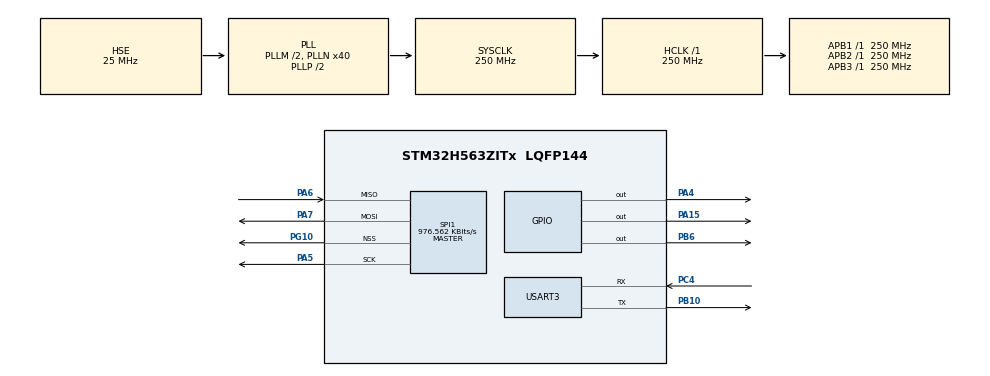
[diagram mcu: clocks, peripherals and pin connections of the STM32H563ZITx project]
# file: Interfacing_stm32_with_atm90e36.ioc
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CORTEX_M33_NS.userName=CORTEX_M33
Mcu.Family=STM32H5
Mcu.Name=STM32H563ZITx
Mcu.Package=LQFP144
NVIC.PriorityGroup=NVIC_PRIORITYGROUP_4
PA15(JTDI).Signal=GPIO_Output
PA4.Signal=GPIO_Output
PA5.Mode=Full_Duplex_Master
PA5.Signal=SPI1_SCK
PA6.Mode=Full_Duplex_Master
PA6.Signal=SPI1_MISO
PA7.Mode=Full_Duplex_Master
PA7.Signal=SPI1_MOSI
PB10.Mode=Asynchronous
PB10.Signal=USART3_TX
PB6.Signal=GPIO_Output
PC4.Mode=Asynchronous
PC4.Signal=USART3_RX
PG10.Mode=NSS_Signal_Hard_Output
PG10.Signal=SPI1_NSS
PH0-OSC_IN(PH0).Mode=HSE-External-Oscillator
PH0-OSC_IN(PH0).Signal=RCC_OSC_IN
PH1-OSC_OUT(PH1).Mode=HSE-External-Oscillator
PH1-OSC_OUT(PH1).Signal=RCC_OSC_OUT
ProjectManager.HeapSize=0x200
ProjectManager.StackSize=0x400
ProjectManager.TargetToolchain=STM32CubeIDE
RCC.ADCFreq_Value=250000000
RCC.AHBFreq_Value=250000000
RCC.APB1Freq_Value=250000000
RCC.APB1TimFreq_Value=250000000
RCC.APB2Freq_Value=250000000
RCC.APB2TimFreq_Value=250000000
RCC.APB3Freq_Value=250000000
RCC.CSI_VALUE=4000000
RCC.CortexFreq_Value=250000000
RCC.EPOD_VALUE=25000000
RCC.HCLKFreq_Value=250000000
RCC.HSE_VALUE=25000000
RCC.HSI48_VALUE=48000000
RCC.HSIDiv=RCC_HSI_DIV1
RCC.HSI_VALUE=64000000
RCC.LSE_VALUE=32768
RCC.LSIRC_VALUE=32000
RCC.PLL2FRACN=0
RCC.PLL3FRACN=0
RCC.PLLFRACN=0
RCC.PLLM=2
RCC.PLLN=40
RCC.PLLSourceVirtual=RCC_PLL1_SOURCE_HSE
RCC.SYSCLKFreq_VALUE=250000000
RCC.SYSCLKSource=RCC_SYSCLKSOURCE_PLLCLK
RCC.USBFreq_Value=48000000
RCC.VCOOutputFreq_Value=500000000
SPI1.BaudRatePrescaler=SPI_BAUDRATEPRESCALER_256
SPI1.CalculateBaudRate=976.562 KBits/s
SPI1.DataSize=SPI_DATASIZE_8BIT
SPI1.Direction=SPI_DIRECTION_2LINES
SPI1.Mode=SPI_MODE_MASTER
SPI1.VirtualNSS=VM_NSSHARD
SPI1.VirtualType=VM_MASTER
USART3.VirtualMode=VM_ASYNC
VP_PWR_VS_SECSignals.Mode=Security/Privilege
board=NUCLEO-H563ZI

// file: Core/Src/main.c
/* USER CODE BEGIN Header */
/**
  ******************************************************************************
  * @file           : main.c
  * @brief          : Main program body
  ******************************************************************************
  * @attention
  *
  * Copyright (c) 2024 STMicroelectronics.
  * All rights reserved.
  *
  * This software is licensed under terms that can be found in the LICENSE file
  * in the root directory of this software component.
  * If no LICENSE file comes with this software, it is provided AS-IS.
  *
  ******************************************************************************
  */
/* USER CODE END Header */
#include "main.h"

/* USER CODE BEGIN Includes */
#include"stdio.h"
#include"stm32h5xx_hal_uart.h"
#include "stm32h5xx_hal_spi.h"
#include"atm90e36.h"

/* USER CODE END Includes */

SPI_HandleTypeDef hspi1;

UART_HandleTypeDef huart3;

/* USER CODE BEGIN PV */
//uint16_t send_data = 0x1234;
//uint16_t rec_data = 0;

/* USER CODE END PV */

void SystemClock_Config(void);
static void MX_GPIO_Init(void);
static void MX_USART3_UART_Init(void);
static void MX_SPI1_Init(void);

/* USER CODE BEGIN 0 */
int __io_putchar(int ch) {
    HAL_UART_Transmit(&huart3, (uint8_t *)&ch, 1, HAL_MAX_DELAY);
    return ch;
}

/* USER CODE END 0 */

int main(void)
{

  /* MCU Configuration--------------------------------------------------------*/

  /* Reset of all peripherals, Initializes the Flash interface and the Systick. */
  HAL_Init();

  /* Configure the system clock */
  SystemClock_Config();

  /* Initialize all configured peripherals */
  MX_GPIO_Init();
  MX_USART3_UART_Init();
  MX_SPI1_Init();
  /* USER CODE BEGIN 2 */

  ATM90E36A_Init();
//  uint16_t temp = 0;

  /* USER CODE END 2 */

  /* Infinite loop */
  while (1)
  {

    /* USER CODE BEGIN 3 */
	  printf("hello\r\n");

	  readEnrgyMeterValues();

//	  printf("Interfacing stm32 with energy meter\r\n");
//	  HAL_SPI_TransmitReceive(&hspi1,(uint8_t*)&send_data, (uint8_t*)&rec_data, 1, HAL_MAX_DELAY);
//	  printf("rece %d\r\n",rec_data);
	  HAL_Delay(1000);
//	  fflush(stdout);
//	  temp = CommEnergyIC(&hspi1, ATM90E36A_READ, Temp, 0);//UrmsA
//	temp =  CommEnergyIC(&hspi1, ATM90E36A_READ, UrmsA, 0);

//	  printf("TEMPERATURE: %d\r\n",temp);

  }
  /* USER CODE END 3 */
}

void SystemClock_Config(void)
{
  RCC_OscInitTypeDef RCC_OscInitStruct = {0};
  RCC_ClkInitTypeDef RCC_ClkInitStruct = {0};

  /** Configure the main internal regulator output voltage
  */
  __HAL_PWR_VOLTAGESCALING_CONFIG(PWR_REGULATOR_VOLTAGE_SCALE0);

  while(!__HAL_PWR_GET_FLAG(PWR_FLAG_VOSRDY)) {}

  /** Initializes the RCC Oscillators according to the specified parameters
  * in the RCC_OscInitTypeDef structure.
  */
  RCC_OscInitStruct.OscillatorType = RCC_OSCILLATORTYPE_HSE;
  RCC_OscInitStruct.HSEState = RCC_HSE_ON;
  RCC_OscInitStruct.PLL.PLLState = RCC_PLL_ON;
  RCC_OscInitStruct.PLL.PLLSource = RCC_PLL1_SOURCE_HSE;
  RCC_OscInitStruct.PLL.PLLM = 2;
  RCC_OscInitStruct.PLL.PLLN = 40;
  RCC_OscInitStruct.PLL.PLLP = 2;
  RCC_OscInitStruct.PLL.PLLQ = 2;
  RCC_OscInitStruct.PLL.PLLR = 2;
  RCC_OscInitStruct.PLL.PLLRGE = RCC_PLL1_VCIRANGE_3;
  RCC_OscInitStruct.PLL.PLLVCOSEL = RCC_PLL1_VCORANGE_WIDE;
  RCC_OscInitStruct.PLL.PLLFRACN = 0;
  if (HAL_RCC_OscConfig(&RCC_OscInitStruct) != HAL_OK)
  {
    Error_Handler();
  }

  /** Initializes the CPU, AHB and APB buses clocks
  */
  RCC_ClkInitStruct.ClockType = RCC_CLOCKTYPE_HCLK|RCC_CLOCKTYPE_SYSCLK
                              |RCC_CLOCKTYPE_PCLK1|RCC_CLOCKTYPE_PCLK2
                              |RCC_CLOCKTYPE_PCLK3;
  RCC_ClkInitStruct.SYSCLKSource = RCC_SYSCLKSOURCE_PLLCLK;
  RCC_ClkInitStruct.AHBCLKDivider = RCC_SYSCLK_DIV1;
  RCC_ClkInitStruct.APB1CLKDivider = RCC_HCLK_DIV1;
  RCC_ClkInitStruct.APB2CLKDivider = RCC_HCLK_DIV1;
  RCC_ClkInitStruct.APB3CLKDivider = RCC_HCLK_DIV1;

  if (HAL_RCC_ClockConfig(&RCC_ClkInitStruct, FLASH_LATENCY_5) != HAL_OK)
  {
    Error_Handler();
  }
}

static void MX_SPI1_Init(void)
{

  /* SPI1 parameter configuration*/
  hspi1.Instance = SPI1;
  hspi1.Init.Mode = SPI_MODE_MASTER;
  hspi1.Init.Direction = SPI_DIRECTION_2LINES;
  hspi1.Init.DataSize = SPI_DATASIZE_8BIT;
  hspi1.Init.CLKPolarity = SPI_POLARITY_LOW;
  hspi1.Init.CLKPhase = SPI_PHASE_1EDGE;
  hspi1.Init.NSS = SPI_NSS_HARD_OUTPUT;
  hspi1.Init.BaudRatePrescaler = SPI_BAUDRATEPRESCALER_256;
  hspi1.Init.FirstBit = SPI_FIRSTBIT_MSB;
  hspi1.Init.TIMode = SPI_TIMODE_DISABLE;
  hspi1.Init.CRCCalculation = SPI_CRCCALCULATION_DISABLE;
  hspi1.Init.CRCPolynomial = 0x7;
  hspi1.Init.NSSPMode = SPI_NSS_PULSE_ENABLE;
  hspi1.Init.NSSPolarity = SPI_NSS_POLARITY_LOW;
  hspi1.Init.FifoThreshold = SPI_FIFO_THRESHOLD_01DATA;
  hspi1.Init.MasterSSIdleness = SPI_MASTER_SS_IDLENESS_00CYCLE;
  hspi1.Init.MasterInterDataIdleness = SPI_MASTER_INTERDATA_IDLENESS_00CYCLE;
  hspi1.Init.MasterReceiverAutoSusp = SPI_MASTER_RX_AUTOSUSP_DISABLE;
  hspi1.Init.MasterKeepIOState = SPI_MASTER_KEEP_IO_STATE_DISABLE;
  hspi1.Init.IOSwap = SPI_IO_SWAP_DISABLE;
  hspi1.Init.ReadyMasterManagement = SPI_RDY_MASTER_MANAGEMENT_INTERNALLY;
  hspi1.Init.ReadyPolarity = SPI_RDY_POLARITY_HIGH;
  if (HAL_SPI_Init(&hspi1) != HAL_OK)
  {
    Error_Handler();
  }

}

static void MX_USART3_UART_Init(void)
{

  huart3.Instance = USART3;
  huart3.Init.BaudRate = 115200;
  huart3.Init.WordLength = UART_WORDLENGTH_8B;
  huart3.Init.StopBits = UART_STOPBITS_1;
  huart3.Init.Parity = UART_PARITY_NONE;
  huart3.Init.Mode = UART_MODE_TX_RX;
  huart3.Init.HwFlowCtl = UART_HWCONTROL_NONE;
  huart3.Init.OverSampling = UART_OVERSAMPLING_16;
  huart3.Init.OneBitSampling = UART_ONE_BIT_SAMPLE_DISABLE;
  huart3.Init.ClockPrescaler = UART_PRESCALER_DIV1;
  huart3.AdvancedInit.AdvFeatureInit = UART_ADVFEATURE_NO_INIT;
  if (HAL_UART_Init(&huart3) != HAL_OK)
  {
    Error_Handler();
  }
  if (HAL_UARTEx_SetTxFifoThreshold(&huart3, UART_TXFIFO_THRESHOLD_1_8) != HAL_OK)
  {
    Error_Handler();
  }
  if (HAL_UARTEx_SetRxFifoThreshold(&huart3, UART_RXFIFO_THRESHOLD_1_8) != HAL_OK)
  {
    Error_Handler();
  }
  if (HAL_UARTEx_DisableFifoMode(&huart3) != HAL_OK)
  {
    Error_Handler();
  }

}

static void MX_GPIO_Init(void)
{
  GPIO_InitTypeDef GPIO_InitStruct = {0};

  /* GPIO Ports Clock Enable */
  __HAL_RCC_GPIOH_CLK_ENABLE();
  __HAL_RCC_GPIOA_CLK_ENABLE();
  __HAL_RCC_GPIOC_CLK_ENABLE();
  __HAL_RCC_GPIOB_CLK_ENABLE();
  __HAL_RCC_GPIOG_CLK_ENABLE();

  /*Configure GPIO pin Output Level */
  HAL_GPIO_WritePin(GPIOA, GPIO_PIN_4|GPIO_PIN_15, GPIO_PIN_RESET);

  /*Configure GPIO pin Output Level */
  HAL_GPIO_WritePin(GPIOB, GPIO_PIN_6, GPIO_PIN_RESET);

  /*Configure GPIO pins : PA4 PA15 */
  GPIO_InitStruct.Pin = GPIO_PIN_4|GPIO_PIN_15;
  GPIO_InitStruct.Mode = GPIO_MODE_OUTPUT_PP;
  GPIO_InitStruct.Pull = GPIO_NOPULL;
  GPIO_InitStruct.Speed = GPIO_SPEED_FREQ_LOW;
  HAL_GPIO_Init(GPIOA, &GPIO_InitStruct);

  /*Configure GPIO pin : PB6 */
  GPIO_InitStruct.Pin = GPIO_PIN_6;
  GPIO_InitStruct.Mode = GPIO_MODE_OUTPUT_PP;
  GPIO_InitStruct.Pull = GPIO_NOPULL;
  GPIO_InitStruct.Speed = GPIO_SPEED_FREQ_LOW;
  HAL_GPIO_Init(GPIOB, &GPIO_InitStruct);

}

void Error_Handler(void)
{
  __disable_irq();
  while (1)
  {
  }
}
